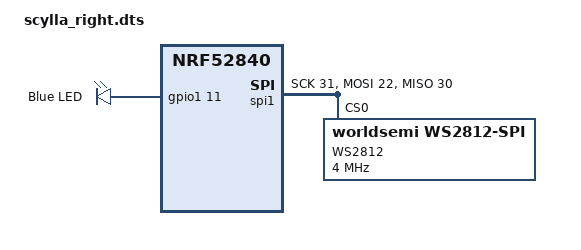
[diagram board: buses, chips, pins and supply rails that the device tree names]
/*
 * Copyright (c) 2021 Thys de Wet (vattern)
 *
 * SPDX-License-Identifier: MIT
 */

/dts-v1/;
#include <nordic/nrf52840_qiaa.dtsi>
#include <dt-bindings/zmk/matrix_transform.h>
#include <dt-bindings/led/led.h>
#include "scylla.dtsi"
&default_transform {
  col-offset = <6>;
};
/ {
leds {
  compatible = "gpio-leds";
  blue_led: led_0 {
    gpios = <&gpio1 11 GPIO_ACTIVE_HIGH>;
    label = "Blue LED";
  };
};
kscan0: kscan {
  col-gpios
      = <&gpio1 4   (GPIO_ACTIVE_HIGH | GPIO_PULL_DOWN)>
      , <&gpio1 2   (GPIO_ACTIVE_HIGH | GPIO_PULL_DOWN)>
      , <&gpio1 3   (GPIO_ACTIVE_HIGH | GPIO_PULL_DOWN)>
      , <&gpio0 3   (GPIO_ACTIVE_HIGH | GPIO_PULL_DOWN)>
      , <&gpio1 15  (GPIO_ACTIVE_HIGH | GPIO_PULL_DOWN)>
      , <&gpio1 13  (GPIO_ACTIVE_HIGH | GPIO_PULL_DOWN)>
      ;
  row-gpios
      = <&gpio1 1   GPIO_ACTIVE_HIGH>
      , <&gpio1 6   GPIO_ACTIVE_HIGH>
      , <&gpio0 10  GPIO_ACTIVE_HIGH>
      , <&gpio0 9   GPIO_ACTIVE_HIGH>
      , <&gpio1 10  GPIO_ACTIVE_HIGH>
      ;
    };
};

&spi1 {
  compatible = "nordic,nrf-spim";
  status = "okay";
  mosi-pin = <22>;
  // Unused pins, needed for SPI definition, but not used by the ws2812 driver itself.
  sck-pin = <31>;
  miso-pin = <30>;

  led_strip: ws2812@0 {
    compatible = "worldsemi,ws2812-spi";
    label = "WS2812";

    /* SPI */
    reg = <0>; /* ignored, but necessary for SPI bindings */
    spi-max-frequency = <4000000>;

    /* WS2812 */
    chain-length = <29>; /* number of LEDs */
    spi-one-frame = <0x70>;
    spi-zero-frame = <0x40>;
    color-mapping = <LED_COLOR_ID_GREEN
                          LED_COLOR_ID_RED
                          LED_COLOR_ID_BLUE>;
  };
};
